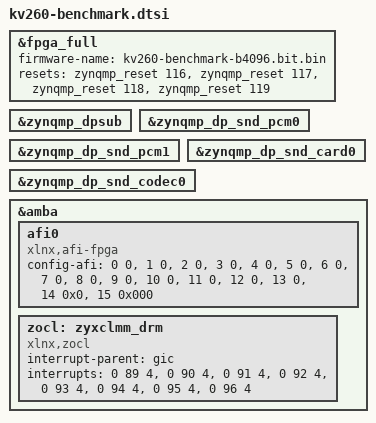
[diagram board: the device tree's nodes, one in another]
// SPDX-License-Identifier: Apache-2.0
/*
 * dts file for Xilinx KV260 smartcam
 *
 * (C) Copyright 2020 - 2021, Xilinx, Inc.
 * Copyright (C) 2023 - 2024, Advanced Micro Devices, Inc.
 *
 */

/dts-v1/;
/plugin/;

&fpga_full {
	#address-cells = <2>;
	#size-cells = <2>;
	firmware-name = "kv260-benchmark-b4096.bit.bin";
	resets = <&zynqmp_reset 116>, <&zynqmp_reset 117>, <&zynqmp_reset 118>, <&zynqmp_reset 119>;
};

&zynqmp_dpsub {
	status = "okay";
};

&zynqmp_dp_snd_pcm0 {
	status = "okay";
};

&zynqmp_dp_snd_pcm1 {
	status = "okay";
};

&zynqmp_dp_snd_card0 {
	status = "okay";
};

&zynqmp_dp_snd_codec0 {
	status = "okay";
};

&amba {
	afi0: afi0 {
		compatible = "xlnx,afi-fpga";
		config-afi = <0 0>, <1 0>, <2 0>, <3 0>, <4 0>, <5 0>, <6 0>, <7 0>, <8 0>, <9 0>, <10 0>, <11 0>, <12 0>, <13 0>, <14 0x0>, <15 0x000>;
	};

	/* zocl */
	zocl: zyxclmm_drm {
		compatible = "xlnx,zocl";
		status = "okay";
		interrupt-parent = <&gic>;
		interrupts = <0 89  4>, <0 90  4>, <0 91  4>, <0 92  4>,
			     <0 93  4>, <0 94  4>, <0 95  4>, <0 96  4>;
	};
};
